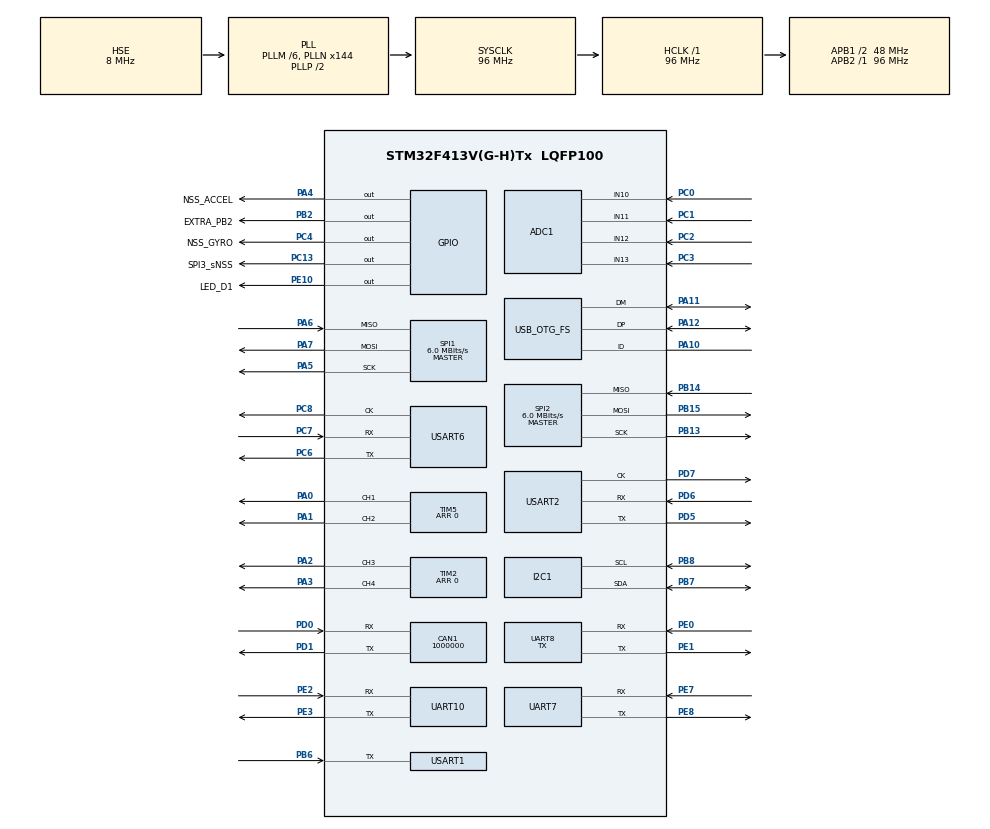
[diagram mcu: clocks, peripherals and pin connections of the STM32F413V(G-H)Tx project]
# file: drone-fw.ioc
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ADC1.Channel-0\#ChannelRegularConversion=ADC_CHANNEL_10
ADC1.Rank-0\#ChannelRegularConversion=1
ADC1.SamplingTime-0\#ChannelRegularConversion=ADC_SAMPLETIME_3CYCLES
ADC1.master=1
CAN1.BS1=CAN_BS1_1TQ
CAN1.BS2=CAN_BS2_1TQ
CAN1.CalculateBaudRate=1000000
CAN1.CalculateTimeBit=1000
CAN1.CalculateTimeQuantum=333.3333333333333
Dma.I2C1_RX.1.Direction=DMA_PERIPH_TO_MEMORY
Dma.I2C1_RX.1.FIFOMode=DMA_FIFOMODE_DISABLE
Dma.I2C1_RX.1.Instance=DMA1_Stream5
Dma.I2C1_RX.1.MemDataAlignment=DMA_MDATAALIGN_BYTE
Dma.I2C1_RX.1.MemInc=DMA_MINC_ENABLE
Dma.I2C1_RX.1.Mode=DMA_NORMAL
Dma.I2C1_RX.1.PeriphDataAlignment=DMA_PDATAALIGN_BYTE
Dma.I2C1_RX.1.PeriphInc=DMA_PINC_DISABLE
Dma.I2C1_RX.1.Priority=DMA_PRIORITY_LOW
Dma.I2C1_TX.2.Direction=DMA_MEMORY_TO_PERIPH
Dma.I2C1_TX.2.FIFOMode=DMA_FIFOMODE_DISABLE
Dma.I2C1_TX.2.Instance=DMA1_Stream7
Dma.I2C1_TX.2.MemDataAlignment=DMA_MDATAALIGN_BYTE
Dma.I2C1_TX.2.MemInc=DMA_MINC_ENABLE
Dma.I2C1_TX.2.Mode=DMA_NORMAL
Dma.I2C1_TX.2.PeriphDataAlignment=DMA_PDATAALIGN_BYTE
Dma.I2C1_TX.2.PeriphInc=DMA_PINC_DISABLE
Dma.I2C1_TX.2.Priority=DMA_PRIORITY_LOW
Dma.Request0=UART8_TX
Dma.Request1=I2C1_RX
Dma.Request10=UART10_RX
Dma.Request11=UART10_TX
Dma.Request12=TIM2_CH2/CH4
Dma.Request13=TIM2_UP/CH3
Dma.Request2=I2C1_TX
Dma.Request3=SPI1_RX
Dma.Request4=SPI1_TX
Dma.Request5=TIM5_CH2
Dma.Request6=TIM5_CH1
Dma.Request7=USART6_RX
Dma.Request8=USART6_TX
Dma.Request9=USART1_RX
Dma.SPI1_RX.3.Direction=DMA_PERIPH_TO_MEMORY
Dma.SPI1_RX.3.FIFOMode=DMA_FIFOMODE_DISABLE
Dma.SPI1_RX.3.Instance=DMA2_Stream0
Dma.SPI1_RX.3.MemDataAlignment=DMA_MDATAALIGN_BYTE
Dma.SPI1_RX.3.MemInc=DMA_MINC_ENABLE
Dma.SPI1_RX.3.Mode=DMA_NORMAL
Dma.SPI1_RX.3.PeriphDataAlignment=DMA_PDATAALIGN_BYTE
Dma.SPI1_RX.3.PeriphInc=DMA_PINC_DISABLE
Dma.SPI1_RX.3.Priority=DMA_PRIORITY_LOW
Dma.SPI1_TX.4.Direction=DMA_MEMORY_TO_PERIPH
Dma.SPI1_TX.4.FIFOMode=DMA_FIFOMODE_DISABLE
Dma.SPI1_TX.4.Instance=DMA2_Stream5
Dma.SPI1_TX.4.MemDataAlignment=DMA_MDATAALIGN_BYTE
Dma.SPI1_TX.4.MemInc=DMA_MINC_ENABLE
Dma.SPI1_TX.4.Mode=DMA_NORMAL
Dma.SPI1_TX.4.PeriphDataAlignment=DMA_PDATAALIGN_BYTE
Dma.SPI1_TX.4.PeriphInc=DMA_PINC_DISABLE
Dma.SPI1_TX.4.Priority=DMA_PRIORITY_LOW
Dma.TIM2_CH2/CH4.12.Direction=DMA_MEMORY_TO_PERIPH
Dma.TIM2_CH2/CH4.12.FIFOMode=DMA_FIFOMODE_ENABLE
Dma.TIM2_CH2/CH4.12.FIFOThreshold=DMA_FIFO_THRESHOLD_1QUARTERFULL
Dma.TIM2_CH2/CH4.12.Instance=DMA1_Stream6
Dma.TIM2_CH2/CH4.12.MemBurst=DMA_MBURST_SINGLE
Dma.TIM2_CH2/CH4.12.MemDataAlignment=DMA_MDATAALIGN_WORD
Dma.TIM2_CH2/CH4.12.MemInc=DMA_MINC_ENABLE
Dma.TIM2_CH2/CH4.12.Mode=DMA_NORMAL
Dma.TIM2_CH2/CH4.12.PeriphBurst=DMA_PBURST_SINGLE
Dma.TIM2_CH2/CH4.12.PeriphDataAlignment=DMA_PDATAALIGN_WORD
Dma.TIM2_CH2/CH4.12.PeriphInc=DMA_PINC_DISABLE
Dma.TIM2_CH2/CH4.12.Priority=DMA_PRIORITY_HIGH
Dma.TIM2_UP/CH3.13.Direction=DMA_MEMORY_TO_PERIPH
Dma.TIM2_UP/CH3.13.FIFOMode=DMA_FIFOMODE_ENABLE
Dma.TIM2_UP/CH3.13.FIFOThreshold=DMA_FIFO_THRESHOLD_1QUARTERFULL
Dma.TIM2_UP/CH3.13.Instance=DMA1_Stream1
Dma.TIM2_UP/CH3.13.MemBurst=DMA_MBURST_SINGLE
Dma.TIM2_UP/CH3.13.MemDataAlignment=DMA_MDATAALIGN_WORD
Dma.TIM2_UP/CH3.13.MemInc=DMA_MINC_ENABLE
Dma.TIM2_UP/CH3.13.Mode=DMA_NORMAL
Dma.TIM2_UP/CH3.13.PeriphBurst=DMA_PBURST_SINGLE
Dma.TIM2_UP/CH3.13.PeriphDataAlignment=DMA_PDATAALIGN_WORD
Dma.TIM2_UP/CH3.13.PeriphInc=DMA_PINC_DISABLE
Dma.TIM2_UP/CH3.13.Priority=DMA_PRIORITY_HIGH
Dma.TIM5_CH1.6.Direction=DMA_MEMORY_TO_PERIPH
Dma.TIM5_CH1.6.FIFOMode=DMA_FIFOMODE_ENABLE
Dma.TIM5_CH1.6.FIFOThreshold=DMA_FIFO_THRESHOLD_1QUARTERFULL
Dma.TIM5_CH1.6.Instance=DMA1_Stream2
Dma.TIM5_CH1.6.MemBurst=DMA_MBURST_SINGLE
Dma.TIM5_CH1.6.MemDataAlignment=DMA_MDATAALIGN_WORD
Dma.TIM5_CH1.6.MemInc=DMA_MINC_ENABLE
Dma.TIM5_CH1.6.Mode=DMA_NORMAL
Dma.TIM5_CH1.6.PeriphBurst=DMA_PBURST_SINGLE
Dma.TIM5_CH1.6.PeriphDataAlignment=DMA_PDATAALIGN_WORD
Dma.TIM5_CH1.6.PeriphInc=DMA_PINC_DISABLE
Dma.TIM5_CH1.6.Priority=DMA_PRIORITY_HIGH
Dma.TIM5_CH2.5.Direction=DMA_MEMORY_TO_PERIPH
Dma.TIM5_CH2.5.FIFOMode=DMA_FIFOMODE_ENABLE
Dma.TIM5_CH2.5.FIFOThreshold=DMA_FIFO_THRESHOLD_1QUARTERFULL
Dma.TIM5_CH2.5.Instance=DMA1_Stream4
Dma.TIM5_CH2.5.MemBurst=DMA_MBURST_SINGLE
Dma.TIM5_CH2.5.MemDataAlignment=DMA_MDATAALIGN_WORD
Dma.TIM5_CH2.5.MemInc=DMA_MINC_ENABLE
Dma.TIM5_CH2.5.Mode=DMA_NORMAL
Dma.TIM5_CH2.5.PeriphBurst=DMA_PBURST_SINGLE
Dma.TIM5_CH2.5.PeriphDataAlignment=DMA_PDATAALIGN_WORD
Dma.TIM5_CH2.5.PeriphInc=DMA_PINC_DISABLE
Dma.TIM5_CH2.5.Priority=DMA_PRIORITY_HIGH
Dma.UART10_RX.10.Direction=DMA_PERIPH_TO_MEMORY
Dma.UART10_RX.10.FIFOMode=DMA_FIFOMODE_DISABLE
Dma.UART10_RX.10.Instance=DMA2_Stream3
Dma.UART10_RX.10.MemDataAlignment=DMA_MDATAALIGN_BYTE
Dma.UART10_RX.10.MemInc=DMA_MINC_ENABLE
Dma.UART10_RX.10.Mode=DMA_CIRCULAR
Dma.UART10_RX.10.PeriphDataAlignment=DMA_PDATAALIGN_BYTE
Dma.UART10_RX.10.PeriphInc=DMA_PINC_DISABLE
Dma.UART10_RX.10.Priority=DMA_PRIORITY_LOW
Dma.UART10_TX.11.Direction=DMA_MEMORY_TO_PERIPH
Dma.UART10_TX.11.FIFOMode=DMA_FIFOMODE_DISABLE
Dma.UART10_TX.11.Instance=DMA2_Stream7
Dma.UART10_TX.11.MemDataAlignment=DMA_MDATAALIGN_BYTE
Dma.UART10_TX.11.MemInc=DMA_MINC_ENABLE
Dma.UART10_TX.11.Mode=DMA_NORMAL
Dma.UART10_TX.11.PeriphDataAlignment=DMA_PDATAALIGN_BYTE
Dma.UART10_TX.11.PeriphInc=DMA_PINC_DISABLE
Dma.UART10_TX.11.Priority=DMA_PRIORITY_LOW
Dma.UART8_TX.0.Direction=DMA_MEMORY_TO_PERIPH
Dma.UART8_TX.0.FIFOMode=DMA_FIFOMODE_DISABLE
Dma.UART8_TX.0.Instance=DMA1_Stream0
Dma.UART8_TX.0.MemDataAlignment=DMA_MDATAALIGN_BYTE
Dma.UART8_TX.0.MemInc=DMA_MINC_ENABLE
Dma.UART8_TX.0.Mode=DMA_NORMAL
Dma.UART8_TX.0.PeriphDataAlignment=DMA_PDATAALIGN_BYTE
Dma.UART8_TX.0.PeriphInc=DMA_PINC_DISABLE
Dma.UART8_TX.0.Priority=DMA_PRIORITY_MEDIUM
Dma.USART1_RX.9.Direction=DMA_PERIPH_TO_MEMORY
Dma.USART1_RX.9.FIFOMode=DMA_FIFOMODE_DISABLE
Dma.USART1_RX.9.Instance=DMA2_Stream2
Dma.USART1_RX.9.MemDataAlignment=DMA_MDATAALIGN_BYTE
Dma.USART1_RX.9.MemInc=DMA_MINC_ENABLE
Dma.USART1_RX.9.Mode=DMA_NORMAL
Dma.USART1_RX.9.PeriphDataAlignment=DMA_PDATAALIGN_BYTE
Dma.USART1_RX.9.PeriphInc=DMA_PINC_DISABLE
Dma.USART1_RX.9.Priority=DMA_PRIORITY_LOW
Dma.USART6_RX.7.Direction=DMA_PERIPH_TO_MEMORY
Dma.USART6_RX.7.FIFOMode=DMA_FIFOMODE_DISABLE
Dma.USART6_RX.7.Instance=DMA2_Stream1
Dma.USART6_RX.7.MemDataAlignment=DMA_MDATAALIGN_BYTE
Dma.USART6_RX.7.MemInc=DMA_MINC_ENABLE
Dma.USART6_RX.7.Mode=DMA_NORMAL
Dma.USART6_RX.7.PeriphDataAlignment=DMA_PDATAALIGN_BYTE
Dma.USART6_RX.7.PeriphInc=DMA_PINC_DISABLE
Dma.USART6_RX.7.Priority=DMA_PRIORITY_LOW
Dma.USART6_TX.8.Direction=DMA_MEMORY_TO_PERIPH
Dma.USART6_TX.8.FIFOMode=DMA_FIFOMODE_DISABLE
Dma.USART6_TX.8.Instance=DMA2_Stream6
Dma.USART6_TX.8.MemDataAlignment=DMA_MDATAALIGN_BYTE
Dma.USART6_TX.8.MemInc=DMA_MINC_ENABLE
Dma.USART6_TX.8.Mode=DMA_NORMAL
Dma.USART6_TX.8.PeriphDataAlignment=DMA_PDATAALIGN_BYTE
Dma.USART6_TX.8.PeriphInc=DMA_PINC_DISABLE
Dma.USART6_TX.8.Priority=DMA_PRIORITY_LOW
FREERTOS.INCLUDE_pcTaskGetTaskName=1
FREERTOS.INCLUDE_uxTaskGetStackHighWaterMark2=1
FREERTOS.INCLUDE_xTaskGetHandle=0
FREERTOS.Tasks01=defaultTask,48,1024,StartDefaultTask,As weak,NULL,Dynamic,NULL,NULL
FREERTOS.configCHECK_FOR_STACK_OVERFLOW=0
FREERTOS.configENABLE_BACKWARD_COMPATIBILITY=0
FREERTOS.configENABLE_FPU=1
FREERTOS.configTOTAL_HEAP_SIZE=131072
FREERTOS.configUSE_CO_ROUTINES=0
FREERTOS.configUSE_NEWLIB_REENTRANT=1
FREERTOS.configUSE_PREEMPTION=1
I2C1.I2C_Mode=I2C_Fast
Mcu.Family=STM32F4
Mcu.Name=STM32F413V(G-H)Tx
Mcu.Package=LQFP100
NVIC.DMA1_Stream0_IRQn=true\:5\:0\:false\:false\:true\:true\:false\:true\:true
NVIC.DMA1_Stream1_IRQn=true\:5\:0\:false\:false\:true\:true\:false\:true\:true
NVIC.DMA1_Stream2_IRQn=true\:5\:0\:false\:false\:true\:true\:false\:true\:true
NVIC.DMA1_Stream4_IRQn=true\:5\:0\:false\:false\:true\:true\:false\:true\:true
NVIC.DMA1_Stream5_IRQn=true\:5\:0\:false\:false\:true\:true\:false\:true\:true
NVIC.DMA1_Stream6_IRQn=true\:5\:0\:false\:false\:true\:true\:false\:true\:true
NVIC.DMA1_Stream7_IRQn=true\:5\:0\:false\:false\:true\:true\:false\:true\:true
NVIC.DMA2_Stream0_IRQn=true\:5\:0\:false\:false\:true\:true\:false\:true\:true
NVIC.DMA2_Stream1_IRQn=true\:5\:0\:false\:false\:true\:true\:false\:true\:true
NVIC.DMA2_Stream2_IRQn=true\:5\:0\:false\:false\:true\:true\:false\:true\:true
NVIC.DMA2_Stream3_IRQn=true\:5\:0\:false\:false\:true\:true\:false\:true\:true
NVIC.DMA2_Stream5_IRQn=true\:5\:0\:false\:false\:true\:true\:false\:true\:true
NVIC.DMA2_Stream6_IRQn=true\:5\:0\:false\:false\:true\:true\:false\:true\:true
NVIC.DMA2_Stream7_IRQn=true\:5\:0\:false\:false\:true\:true\:false\:true\:true
NVIC.I2C1_EV_IRQn=true\:5\:0\:false\:false\:true\:true\:true\:true\:true
NVIC.PriorityGroup=NVIC_PRIORITYGROUP_4
NVIC.SPI1_IRQn=true\:5\:0\:false\:false\:true\:true\:true\:true\:true
NVIC.SPI2_IRQn=true\:5\:0\:false\:false\:true\:true\:true\:true\:true
NVIC.TIM2_IRQn=true\:5\:0\:false\:false\:true\:true\:true\:true\:true
NVIC.TIM4_IRQn=true\:15\:0\:false\:false\:true\:false\:false\:true\:true
NVIC.TIM5_IRQn=true\:5\:0\:false\:false\:true\:true\:true\:true\:true
NVIC.TimeBase=TIM4_IRQn
NVIC.TimeBaseIP=TIM4
NVIC.UART10_IRQn=true\:5\:0\:false\:false\:true\:true\:true\:true\:true
NVIC.UART7_IRQn=true\:5\:0\:false\:false\:true\:true\:true\:true\:true
NVIC.UART8_IRQn=true\:5\:0\:false\:false\:true\:true\:true\:true\:true
NVIC.USART2_IRQn=true\:5\:0\:false\:false\:true\:true\:true\:true\:true
PA0.Signal=S_TIM5_CH1
PA1.Signal=S_TIM5_CH2
PA10.Mode=OTG/Dual_Role_Device
PA10.Signal=USB_OTG_FS_ID
PA11.Mode=OTG/Dual_Role_Device
PA11.Signal=USB_OTG_FS_DM
PA12.Mode=OTG/Dual_Role_Device
PA12.Signal=USB_OTG_FS_DP
PA13.Mode=Serial_Wire
PA13.Signal=SYS_JTMS-SWDIO
PA14.Mode=Serial_Wire
PA14.Signal=SYS_JTCK-SWCLK
PA2.Signal=S_TIM2_CH3
PA3.Signal=S_TIM2_CH4
PA4.GPIO_Label=NSS_ACCEL
PA4.PinState=GPIO_PIN_SET
PA4.Signal=GPIO_Output
PA5.Mode=Full_Duplex_Master
PA5.Signal=SPI1_SCK
PA6.Mode=Full_Duplex_Master
PA6.Signal=SPI1_MISO
PA7.Mode=Full_Duplex_Master
PA7.Signal=SPI1_MOSI
PA9.Signal=USB_OTG_FS_VBUS
PB0.Signal=S_TIM3_CH3
PB1.Signal=S_TIM3_CH4
PB10.Signal=I2C2_SCL
PB12.Signal=SPI2_NSS
PB13.Mode=Full_Duplex_Master
PB13.Signal=SPI2_SCK
PB14.Mode=Full_Duplex_Master
PB14.Signal=SPI2_MISO
PB15.Mode=Full_Duplex_Master
PB15.Signal=SPI2_MOSI
PB2.GPIO_Label=EXTRA_PB2
PB2.GPIO_ModeDefaultOutputPP=GPIO_MODE_OUTPUT_OD
PB2.GPIO_PuPd=GPIO_NOPULL
PB2.GPIO_Speed=GPIO_SPEED_FREQ_MEDIUM
PB2.Signal=GPIO_Output
PB3.Signal=SYS_JTDO-SWO
PB4.Signal=S_TIM3_CH1
PB5.Signal=S_TIM3_CH2
PB6.Mode=Half_duplex(single_wire_mode)
PB6.Signal=USART1_TX
PB7.Mode=I2C
PB7.Signal=I2C1_SDA
PB8.Mode=I2C
PB8.Signal=I2C1_SCL
PB9.Signal=I2C2_SDA
PC0.Signal=ADCx_IN10
PC1.Signal=ADCx_IN11
PC10.Signal=SPI3_SCK
PC11.Signal=SPI3_MISO
PC12.Signal=SPI3_MOSI
PC13.GPIO_Label=SPI3_sNSS
PC13.Signal=GPIO_Output
PC2.Signal=ADCx_IN12
PC3.Signal=ADCx_IN13
PC4.GPIO_Label=NSS_GYRO
PC4.GPIO_PuPd=GPIO_NOPULL
PC4.PinState=GPIO_PIN_SET
PC4.Signal=GPIO_Output
PC6.Mode=Synchronous
PC6.Signal=USART6_TX
PC7.Mode=Synchronous
PC7.Signal=USART6_RX
PC8.Mode=Synchronous
PC8.Signal=USART6_CK
PC9.Signal=S_TIM8_CH4
PD0.Mode=CAN_Activate
PD0.Signal=CAN1_RX
PD1.Mode=CAN_Activate
PD1.Signal=CAN1_TX
PD10.Signal=USART3_CK
PD12.Signal=FMPI2C1_SCL
PD13.Signal=FMPI2C1_SDA
PD14.Signal=UART9_RX
PD15.Signal=UART9_TX
PD3.Signal=USART2_CTS
PD4.Signal=USART2_RTS
PD5.Mode=Synchronous
PD5.Signal=USART2_TX
PD6.Mode=Synchronous
PD6.Signal=USART2_RX
PD7.Mode=Synchronous
PD7.Signal=USART2_CK
PD8.Signal=USART3_TX
PD9.Signal=USART3_RX
PE0.Mode=Asynchronous
PE0.Signal=UART8_RX
PE1.Mode=Asynchronous
PE1.Signal=UART8_TX
PE10.GPIO_Label=LED_D1
PE10.GPIO_ModeDefaultOutputPP=GPIO_MODE_OUTPUT_OD
PE10.GPIO_PuPd=GPIO_NOPULL
PE10.PinState=GPIO_PIN_RESET
PE10.Signal=GPIO_Output
PE11.Signal=S_TIM1_CH2
PE12.Signal=SPI4_SCK
PE13.Signal=S_TIM1_CH3
PE14.Signal=S_TIM1_CH4
PE2.Mode=Asynchronous
PE2.Signal=UART10_RX
PE3.Mode=Asynchronous
PE3.Signal=UART10_TX
PE4.Signal=SPI4_NSS
PE5.Signal=SPI4_MISO
PE6.Signal=SPI4_MOSI
PE7.Mode=Asynchronous
PE7.Signal=UART7_RX
PE8.Mode=Asynchronous
PE8.Signal=UART7_TX
PE9.Signal=S_TIM1_CH1
PH0\ -\ OSC_IN.Mode=HSE-External-Oscillator
PH0\ -\ OSC_IN.Signal=RCC_OSC_IN
PH1\ -\ OSC_OUT.Mode=HSE-External-Oscillator
PH1\ -\ OSC_OUT.Signal=RCC_OSC_OUT
ProjectManager.HeapSize=0x200
ProjectManager.StackSize=0x400
ProjectManager.TargetToolchain=STM32CubeIDE
RCC.AHBFreq_Value=96000000
RCC.APB1CLKDivider=RCC_HCLK_DIV2
RCC.APB1Freq_Value=48000000
RCC.APB1TimFreq_Value=96000000
RCC.APB2Freq_Value=96000000
RCC.APB2TimFreq_Value=96000000
RCC.CortexFreq_Value=96000000
RCC.HCLKFreq_Value=96000000
RCC.HSE_VALUE=8000000
RCC.PLLM=6
RCC.PLLN=144
RCC.PLLQ=4
RCC.PWREXT_OverDrive=PWREXT_OverDrive_DESACTIVATED
RCC.SYSCLKFreq_VALUE=96000000
RCC.SYSCLKSource=RCC_SYSCLKSOURCE_PLLCLK
RCC.USBFreq_Value=48000000
RCC.VCOOutputFreq_Value=192000000
SH.ADCx_IN10.0=ADC1_IN10,IN10
SH.ADCx_IN11.0=ADC1_IN11,IN11
SH.ADCx_IN12.0=ADC1_IN12,IN12
SH.ADCx_IN13.0=ADC1_IN13,IN13
SH.S_TIM1_CH1.0=TIM1_CH1
SH.S_TIM1_CH2.0=TIM1_CH2
SH.S_TIM1_CH3.0=TIM1_CH3
SH.S_TIM1_CH4.0=TIM1_CH4
SH.S_TIM2_CH3.0=TIM2_CH3,PWM Generation3 CH3
SH.S_TIM2_CH4.0=TIM2_CH4,PWM Generation4 CH4
SH.S_TIM3_CH1.0=TIM3_CH1
SH.S_TIM3_CH2.0=TIM3_CH2
SH.S_TIM3_CH3.0=TIM3_CH3
SH.S_TIM3_CH4.0=TIM3_CH4
SH.S_TIM5_CH1.0=TIM5_CH1,PWM Generation1 CH1
SH.S_TIM5_CH2.0=TIM5_CH2,PWM Generation2 CH2
SH.S_TIM8_CH4.0=TIM8_CH4
SPI1.BaudRatePrescaler=SPI_BAUDRATEPRESCALER_16
SPI1.CalculateBaudRate=6.0 MBits/s
SPI1.DataSize=SPI_DATASIZE_8BIT
SPI1.Direction=SPI_DIRECTION_2LINES
SPI1.Mode=SPI_MODE_MASTER
SPI1.VirtualType=VM_MASTER
SPI2.BaudRatePrescaler=SPI_BAUDRATEPRESCALER_8
SPI2.CRCCalculation=SPI_CRCCALCULATION_DISABLE
SPI2.CalculateBaudRate=6.0 MBits/s
SPI2.DataSize=SPI_DATASIZE_8BIT
SPI2.Direction=SPI_DIRECTION_2LINES
SPI2.Mode=SPI_MODE_MASTER
SPI2.TIMode=SPI_TIMODE_DISABLE
SPI2.VirtualNSS=VM_NSSHARD
SPI2.VirtualType=VM_MASTER
TIM2.Channel-PWM\ Generation3\ CH3=TIM_CHANNEL_3
TIM2.Channel-PWM\ Generation4\ CH4=TIM_CHANNEL_4
TIM2.Period=0
TIM5.Channel-PWM\ Generation1\ CH1=TIM_CHANNEL_1
TIM5.Channel-PWM\ Generation2\ CH2=TIM_CHANNEL_2
TIM5.Period=0
UART10.VirtualMode=Asynchronous
UART7.VirtualMode=Asynchronous
UART8.Mode=MODE_TX
UART8.VirtualMode=Asynchronous
USART1.Mode=MODE_RX
USART1.VirtualMode=VM_ASYNC
USART2.VirtualMode=VM_SYNC
USART6.VirtualMode=VM_SYNC
VP_FREERTOS_VS_CMSIS_V2.Mode=CMSIS_V2
VP_SYS_VS_tim4.Mode=TIM4
board=custom

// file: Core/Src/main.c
/* USER CODE BEGIN Header */
/**
  ******************************************************************************
  * @file           : main.c
  * @brief          : Main program body
  ******************************************************************************
  * @attention
  *
  * Copyright (c) 2023 STMicroelectronics.
  * All rights reserved.
  *
  * This software is licensed under terms that can be found in the LICENSE file
  * in the root directory of this software component.
  * If no LICENSE file comes with this software, it is provided AS-IS.
  *
  ******************************************************************************
  */
/* USER CODE END Header */
#include "main.h"
#include "cmsis_os.h"
#include "adc.h"
#include "can.h"
#include "dma.h"
#include "i2c.h"
#include "spi.h"
#include "tim.h"
#include "usart.h"
#include "usb_otg.h"
#include "gpio.h"

/* USER CODE BEGIN Includes */
#include "user_main.h"
/* USER CODE END Includes */

void SystemClock_Config(void);
void MX_FREERTOS_Init(void);

int main(void)
{

  /* MCU Configuration--------------------------------------------------------*/

  /* Reset of all peripherals, Initializes the Flash interface and the Systick. */
  HAL_Init();

  /* Configure the system clock */
  SystemClock_Config();

  /* Initialize all configured peripherals */
  MX_GPIO_Init();
  MX_DMA_Init();
  MX_ADC1_Init();
  MX_CAN1_Init();
  MX_SPI2_Init();
  MX_USART1_UART_Init();
  MX_USART2_Init();
  MX_USART6_Init();
  MX_USB_OTG_FS_USB_Init();
  MX_UART8_Init();
  MX_UART7_Init();
  MX_I2C1_Init();
  MX_SPI1_Init();
  MX_TIM5_Init();
  MX_TIM2_Init();
  MX_UART10_Init();
  /* USER CODE BEGIN 2 */
  preInit();
  /* USER CODE END 2 */

  /* Init scheduler */
  osKernelInitialize();

  /* Call init function for freertos objects (in cmsis_os2.c) */
  MX_FREERTOS_Init();

  /* Start scheduler */
  osKernelStart();

  /* We should never get here as control is now taken by the scheduler */

  /* Infinite loop */
  while (1)
  {

  }
}

void SystemClock_Config(void)
{
  RCC_OscInitTypeDef RCC_OscInitStruct = {0};
  RCC_ClkInitTypeDef RCC_ClkInitStruct = {0};

  /** Configure the main internal regulator output voltage
  */
  __HAL_RCC_PWR_CLK_ENABLE();
  __HAL_PWR_VOLTAGESCALING_CONFIG(PWR_REGULATOR_VOLTAGE_SCALE1);

  /** Initializes the RCC Oscillators according to the specified parameters
  * in the RCC_OscInitTypeDef structure.
  */
  RCC_OscInitStruct.OscillatorType = RCC_OSCILLATORTYPE_HSE;
  RCC_OscInitStruct.HSEState = RCC_HSE_ON;
  RCC_OscInitStruct.PLL.PLLState = RCC_PLL_ON;
  RCC_OscInitStruct.PLL.PLLSource = RCC_PLLSOURCE_HSE;
  RCC_OscInitStruct.PLL.PLLM = 6;
  RCC_OscInitStruct.PLL.PLLN = 144;
  RCC_OscInitStruct.PLL.PLLP = RCC_PLLP_DIV2;
  RCC_OscInitStruct.PLL.PLLQ = 4;
  RCC_OscInitStruct.PLL.PLLR = 2;
  if (HAL_RCC_OscConfig(&RCC_OscInitStruct) != HAL_OK)
  {
    Error_Handler();
  }

  /** Initializes the CPU, AHB and APB buses clocks
  */
  RCC_ClkInitStruct.ClockType = RCC_CLOCKTYPE_HCLK|RCC_CLOCKTYPE_SYSCLK
                              |RCC_CLOCKTYPE_PCLK1|RCC_CLOCKTYPE_PCLK2;
  RCC_ClkInitStruct.SYSCLKSource = RCC_SYSCLKSOURCE_PLLCLK;
  RCC_ClkInitStruct.AHBCLKDivider = RCC_SYSCLK_DIV1;
  RCC_ClkInitStruct.APB1CLKDivider = RCC_HCLK_DIV2;
  RCC_ClkInitStruct.APB2CLKDivider = RCC_HCLK_DIV1;

  if (HAL_RCC_ClockConfig(&RCC_ClkInitStruct, FLASH_LATENCY_3) != HAL_OK)
  {
    Error_Handler();
  }
}

void HAL_TIM_PeriodElapsedCallback(TIM_HandleTypeDef *htim)
{
  if (htim->Instance == TIM4) {
    HAL_IncTick();
  }
}

void Error_Handler(void)
{
  /* USER CODE BEGIN Error_Handler_Debug */
  /* User can add his own implementation to report the HAL error return state */
  //__disable_irq();
  taskError();
  while (1)
  {
      // allow other threads (logger)
      vTaskDelay(50);
  }
  /* USER CODE END Error_Handler_Debug */
}

#ifdef  USE_FULL_ASSERT
/**
  * @brief  Reports the name of the source file and the source line number
  *         where the assert_param error has occurred.
  * @param  file: pointer to the source file name
  * @param  line: assert_param error line source number
  * @retval None
  */
void assert_failed(uint8_t *file, uint32_t line)
{
  /* USER CODE BEGIN 6 */
  /* User can add his own implementation to report the file name and line number,
     ex: printf("Wrong parameters value: file %s on line %d\r\n", file, line) */
    user_assert_failed(file, line);
  /* USER CODE END 6 */
}
#endif /* USE_FULL_ASSERT */

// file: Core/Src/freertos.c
/* USER CODE BEGIN Header */
/**
  ******************************************************************************
  * File Name          : freertos.c
  * Description        : Code for freertos applications
  ******************************************************************************
  * @attention
  *
  * Copyright (c) 2023 STMicroelectronics.
  * All rights reserved.
  *
  * This software is licensed under terms that can be found in the LICENSE file
  * in the root directory of this software component.
  * If no LICENSE file comes with this software, it is provided AS-IS.
  *
  ******************************************************************************
  */
/* USER CODE END Header */

#include "FreeRTOS.h"
#include "task.h"
#include "main.h"
#include "cmsis_os.h"

/* USER CODE BEGIN Includes */
#include "user_main.h"
/* USER CODE END Includes */

/* Definitions for defaultTask */
osThreadId_t defaultTaskHandle;
const osThreadAttr_t defaultTask_attributes = {
  .name = "defaultTask",
  .stack_size = 1024 * 4,
  .priority = (osPriority_t) osPriorityRealtime,
};

void StartDefaultTask(void *argument);

void MX_FREERTOS_Init(void); /* (MISRA C 2004 rule 8.1) */

void MX_FREERTOS_Init(void) {

  /* Create the thread(s) */
  /* creation of defaultTask */
  defaultTaskHandle = osThreadNew(StartDefaultTask, NULL, &defaultTask_attributes);

}

__weak void StartDefaultTask(void *argument)
{
  for(;;)
  {
    osDelay(1);
  }
}
